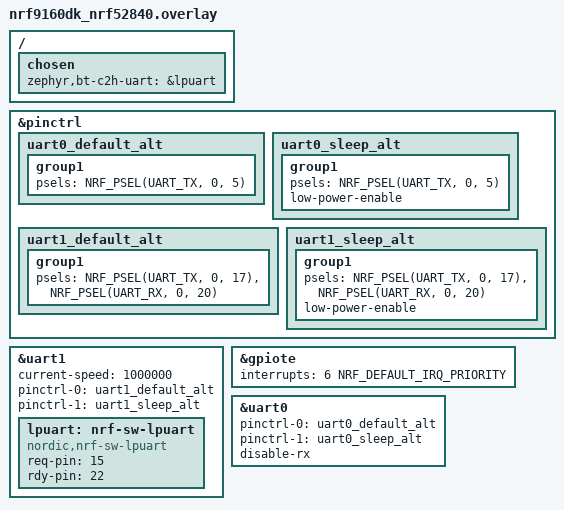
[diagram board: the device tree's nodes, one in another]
/* SPDX-License-Identifier: LicenseRef-Nordic-5-Clause */

#include <nrf52840/nrf9160dk_nrf52840_reset_on_if5.dtsi>
#include <nrf52840/nrf9160dk_uart1_on_if0_3.dtsi>

&pinctrl {
	uart0_default_alt: uart0_default_alt {
		group1 {
			psels = <NRF_PSEL(UART_TX, 0, 5)>;
		};
	};

	uart0_sleep_alt: uart0_sleep_alt {
		group1 {
			psels = <NRF_PSEL(UART_TX, 0, 5)>;
			low-power-enable;
		};
	};

	uart1_default_alt: uart1_default_alt {
		group1 {
			psels = <NRF_PSEL(UART_TX, 0, 17)>,
				<NRF_PSEL(UART_RX, 0, 20)>;
		};
	};

	uart1_sleep_alt: uart1_sleep_alt {
		group1 {
			psels = <NRF_PSEL(UART_TX, 0, 17)>,
				<NRF_PSEL(UART_RX, 0, 20)>;
			low-power-enable;
		};
	};

};

&uart1 {
	current-speed = <1000000>;
	pinctrl-0 = <&uart1_default_alt>;
	pinctrl-1 = <&uart1_sleep_alt>;
	pinctrl-names = "default", "sleep";

	lpuart: nrf-sw-lpuart {
		compatible = "nordic,nrf-sw-lpuart";
		status = "okay";
		req-pin = <15>; /* <&interface_to_nrf9160 2 0>; */
		rdy-pin = <22>; /* <&interface_to_nrf9160 3 0>; */
	};
};

/ {
	chosen {
		zephyr,bt-c2h-uart=&lpuart;
	};
};

&gpiote {
	interrupts = <6 NRF_DEFAULT_IRQ_PRIORITY>;
};

/* Disabling uart rx pin to get low power */
&uart0 {
	pinctrl-0 = <&uart0_default_alt>;
	pinctrl-1 = <&uart0_sleep_alt>;
	pinctrl-names = "default", "sleep";
	disable-rx;
};
